# MIK32 register map
Vendor: Mikron; Series: MIK32; File version: 1.0
Registers are 32-bit, read-write, reset 0x0 unless marked. A register's access mark holds for its fields unless they carry their own. Offsets are from the block's base; [hi:lo] are bit positions; 'fields as' and 'values as' point back to an identical list.

## PM — Блок управления питанием и тактированием
Base 0x00050000
0x00 DIV_AHB — Задает значение делителя шины AHB. Частота шины AHB (FAHB) рассчитывается, как FSYS/( DIV_AHB+1)
0x04 DIV_APB_M — Задает значение делителя шины APB_M. Частота шины APB_M (FAPM_M) рассчитывается, как FAPB/( Div_APM_M+1)
0x08 DIV_APB_P — Задает значение делителя шины APB_P. Частота шины APB_P (FAPM_P) рассчитывается, как FAPB/( Div_APM_P+1)
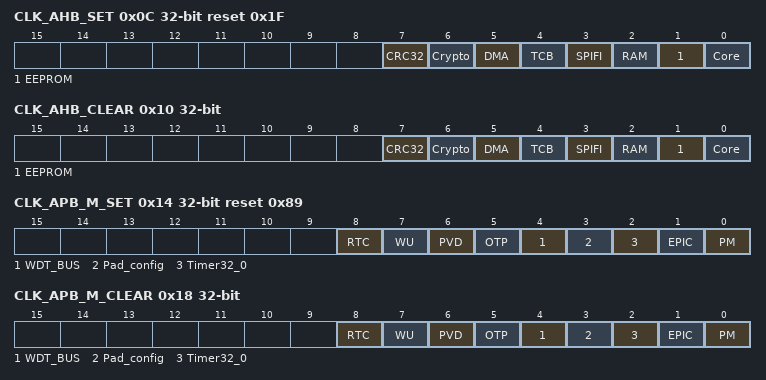
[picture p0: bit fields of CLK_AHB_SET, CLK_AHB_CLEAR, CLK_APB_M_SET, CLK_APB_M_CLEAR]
0x0C CLK_AHB_SET reset 0x1F — Регистр включения тактированием устройств на шине AHB
  [all] fields
    0=Disable (Тактирование выключено); 1=Enable (Тактирование включено)
  [7] CRC32
  [6] Crypto
  [5] DMA
  [4] TCB
  [3] SPIFI
  [2] RAM
  [1] EEPROM
  [0] Core — Ядро
0x10 CLK_AHB_CLEAR — Регистр выключения тактированием устройств на шине AHB. Каждому биту соответствует устройство, аналогично CLK_AHB_SET
  [all] fields
    on read: 0=Disable (Тактирование выключено); 1=Enable (Тактирование включено) | on write: 1=Disable (Тактирование выключено); 0=Enable (Тактирование включено)
  [7] CRC32
  [6] Crypto
  [5] DMA
  [4] TCB
  [3] SPIFI
  [2] RAM
  [1] EEPROM
  [0] Core — Ядро
0x14 CLK_APB_M_SET reset 0x89 — Регистр включения тактированием устройств на шине APB_M. Каждому биту соответствует устройство
  [all] fields
    values as the fields of CLK_AHB_SET
  [8] RTC — RTC батарейного домена
  [7] WU — Блок WakeUp (WU) батарейного домена
  [6] PVD — Монитор питания системного домена
  [5] OTP
  [4] WDT_BUS — Сторожевой таймер шины
  [3] Pad_config — Контроллер выводов
  [2] Timer32_0 — Таймер32_0
  [1] EPIC — Контроллер прерываний
  [0] PM — Блок управления питанием (PM - Power Monitor)
0x18 CLK_APB_M_CLEAR — Регистр выключения тактированием устройств на шине APB_M. Каждому биту соответствует устройство, аналогично Clk_APB_M_Set
  [all] fields
    values as the fields of CLK_AHB_CLEAR
  [8] RTC — RTC батарейного домена
  [7] WU — Блок WakeUp (WU) батарейного домена
  [6] PVD — Монитор питания системного домена
  [5] OTP
  [4] WDT_BUS — Сторожевой таймер шины
  [3] Pad_config — Контроллер выводов
  [2] Timer32_0 — Таймер32_0
  [1] EPIC — Контроллер прерываний
  [0] PM — Блок управления питанием (PM - Power Monitor)
0x1C CLK_APB_P_SET — Регистр включения тактированием устройств на шине APB_P. Каждому биту соответствует одно устройство
  [all] fields
    values as the fields of CLK_AHB_SET
  [15] Analog_regs — Регистры аналоговых блоков
  [15] GPIO_IRQ — Схема формирования прерываний GPIO
  [14] GPIO_2
  [13] GPIO_1
  [12] GPIO_0
  [11] I2C_1
  [10] I2C_0
  [9] SPI_1
  [8] SPI_0
  [7] Timer32_2
  [6] Timer32_1
  [5] Timer16_2
  [4] Timer16_1
  [3] Timer16_0
  [2] UART_1
  [1] UART_0
  [0] WDT — Сторожевой таймер
0x20 CLK_APB_P_CLEAR — Регистр выключения тактированием устройств на шине APB_P. Каждому биту соответствует устройство, аналогично CLK_APB_P_SET
  [all] fields
    values as the fields of CLK_AHB_CLEAR
  [15] Analog_regs — Регистры аналоговых блоков
  [15] GPIO_IRQ — Схема формирования прерываний GPIO
  [14] GPIO_2
  [13] GPIO_1
  [12] GPIO_0
  [11] I2C_1
  [10] I2C_0
  [9] SPI_1
  [8] SPI_0
  [7] Timer32_2
  [6] Timer32_1
  [5] Timer16_2
  [4] Timer16_1
  [3] Timer16_0
  [2] UART_1
  [1] UART_0
  [0] WDT — Сторожевой таймер
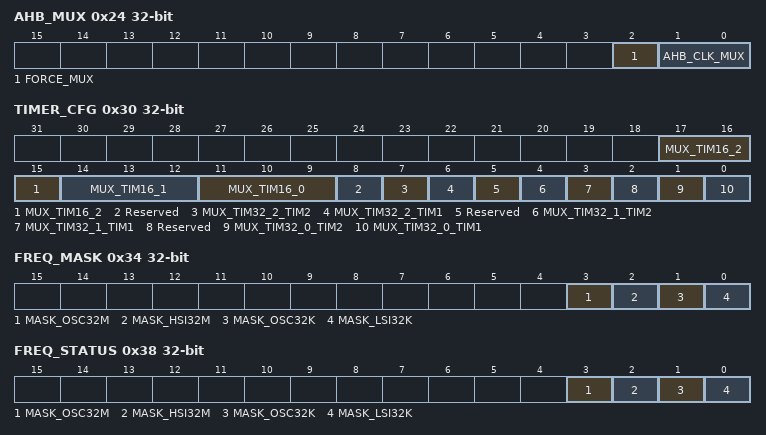
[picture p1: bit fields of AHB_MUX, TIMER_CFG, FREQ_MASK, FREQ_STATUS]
0x24 AHB_MUX — Настройка источника тактирования системы
  [2] FORCE_MUX — Запрет на принудительное переключение с выбранного источника тактирования при пропадании тактирования
    0=Unfixed (Разрешение автоматической смены частоты); 1=Fixed (Запрет автоматической смены частоты)
  [1:0] AHB_CLK_MUX — Источника тактирования системы
    0=OSC32M (Внешний OSC32M); 1=HSI32M (Внутренний HSI32M); 2=OSC32K (Внешний OSC32K); 3=LSI32K (Внутренний LSI32К)
0x28 WDT_CLK_MUX — Выбор источника тактирования сторожевого таймера: 0 – внешний OSC32M; 1 – внутренний HSI32M; 2 – внешний OSC32K; 3 – внутренний LSI32К;
  [1:0] WDT_CLK_MUX — Выбор источника тактирования сторожевого таймера
    values as AHB_MUX.AHB_CLK_MUX
0x2C CPU_RTC_CLK_MUX — Выбор источника тактирования RTC для системного таймера в составе ядра
  [0] CPU_RTC_CLK_MUX — Выбор источника тактирования сторожевого таймера
    0=OSC32K (Внешний OSC32K); 1=LSI32K (Внутренний LSI32К)
0x30 TIMER_CFG — Выбор источника тактирования для таймеров
  [17:15] MUX_TIM16_2 — Выбор тактового сигнала для Timer16_2
    0=SYS_CLK (Системная частота (sys_clk)); 1=HCLK (Частота шины AHB (hclk)); 2=OSC32M (Частота внешнего осциллятора OSC32М); 3=HSI32M (Частота встроенного осциллятора HSI32M); 4=OSC32K (частота внешнего осциллятора OSC32К); 5=LSI32K (Частота встроенного осциллятора LSI32K)
  [14:12] MUX_TIM16_1 — Выбор тактового сигнала для Timer16_1
    values as MUX_TIM16_2
  [11:9] MUX_TIM16_0 — Выбор тактового сигнала для Timer16_0
    values as MUX_TIM16_2
  [8] Reserved — Зарезервировано
  [7] MUX_TIM32_2_TIM2 — Выбор асинхронного тактового сигнала для входа TIM2 Timer32_2
    0=OSC32K; 1=LSI32K
  [6] MUX_TIM32_2_TIM1 — Выбор синхронного тактового сигнала для входа TIM1 Timer32_2
    0=SYS_CLK (Системная частота (sys_clk)); 1=HCLK (Частота шины AHB (hclk))
  [5] Reserved — Зарезервировано
  [4] MUX_TIM32_1_TIM2 — Выбор асинхронного тактового сигнала для входа TIM2 Timer32_1
    0=OSC32K; 1=LSI32K
  [3] MUX_TIM32_1_TIM1 — Выбор синхронного тактового сигнала для входа TIM1 Timer32_1
    values as MUX_TIM32_2_TIM1
  [2] Reserved — Зарезервировано
  [1] MUX_TIM32_0_TIM2 — Выбор асинхронного тактового сигнала для входа TIM2 Timer32_0
    0=OSC32K; 1=LSI32K
  [0] MUX_TIM32_0_TIM1 — Выбор синхронного тактового сигнала для входа TIM1 Timer32_0
    values as MUX_TIM32_2_TIM1
0x34 FREQ_MASK — Настройки прерываний монитора частоты
  [all] fields
    0=Disable (Запретить прерывание); 1=Enable (Разрешить прерывание)
  [3] MASK_OSC32M — Разрешение прерывания при пропадании частоты внешнего осциллятора 32 МГц
  [2] MASK_HSI32M — Разрешение прерывания при пропадании частоты HSI32M
  [1] MASK_OSC32K — Разрешение прерывания при пропадании частоты внешнего осциллятора 32 кГц
  [0] MASK_LSI32K — Разрешение прерывания при пропадании частоты LSI32K
0x38 FREQ_STATUS — Статус монитора частоты
  [3] MASK_OSC32M ro — Статус частоты внешнего осциллятора 32 МГц OSC32M
  [2] MASK_HSI32M ro — Статус частоты HSI32M
  [1] MASK_OSC32K ro — Статус частоты внешнего осциллятора 32 кГц OSC32K
  [0] MASK_LSI32K ro — Статус частоты LSI32K
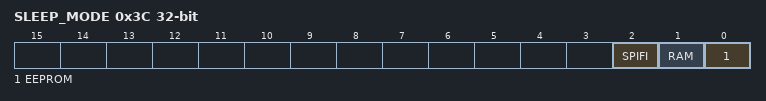
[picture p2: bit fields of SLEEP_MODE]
0x3C SLEEP_MODE — Переход в спящий режим осуществляется записью в данный регистр. При записи отключается тактирование ядра. В зависимости от записываемого значения отключается тактирование модулей: SLEEP_MODE [0] = 1 – отключение тактирования ядра; SLEEP_MODE [1] = 1 – отключение тактирования EEPROM; SLEEP_MODE [2] = 1 – отключение тактирования ОЗУ; SLEEP_MODE [3] = 1 – отключение тактирования контроллера SPIFI.
  [2] SPIFI ro — Отключение тактирования контроллера SPIFI
  [1] RAM ro — Отключение тактирования ОЗУ
  [0] EEPROM ro — Отключение тактирования EEPROM

## Notices in the file
MIT License
Copyright (c) 2024 Лаборатория системных разработок, Mikron
Permission is hereby granted, free of charge, to any person obtaining a copy
of this software and associated documentation files (the "Software"), to deal
in the Software without restriction, including without limitation the rights
to use, copy, modify, merge, publish, distribute, sublicense, and/or sell
copies of the Software, and to permit persons to whom the Software is
furnished to do so, subject to the following conditions:
The above copyright notice and this permission notice shall be included in all
copies or substantial portions of the Software.
THE SOFTWARE IS PROVIDED "AS IS", WITHOUT WARRANTY OF ANY KIND, EXPRESS OR
IMPLIED, INCLUDING BUT NOT LIMITED TO THE WARRANTIES OF MERCHANTABILITY,
FITNESS FOR A PARTICULAR PURPOSE AND NONINFRINGEMENT. IN NO EVENT SHALL THE
AUTHORS OR COPYRIGHT HOLDERS BE LIABLE FOR ANY CLAIM, DAMAGES OR OTHER
LIABILITY, WHETHER IN AN ACTION OF CONTRACT, TORT OR OTHERWISE, ARISING FROM,
OUT OF OR IN CONNECTION WITH THE SOFTWARE OR THE USE OR OTHER DEALINGS IN THE
SOFTWARE.
